# DSS_EDP0_V2A_CORE_VP_REGS_APB register map
Vendor: Texas Instruments
Registers are 32-bit, access not given, reset 0x0 unless marked. A register's access mark holds for its fields unless they carry their own. Offsets are as the file gives them; [hi:lo] are bit positions; {n}, {i} and the like mark numbered series.

## DSS_EDP0_V2A_CORE_VP_REGS_APB (part 3 of 4)
0x226C V2A__CORE_VP__REGS_APB_DP_MTPH_STATUS_p — MTP header status. Relevant only in MST mode.
  [0] MTPH_ACT_STATUS ro — Status of ACT insertion. Returns 1 until ACT sequence completes.
0x2300 V2A__CORE_VP__REGS_APB_DPTX_LANE_EN_p — DPTX lane enable
  [3:0] DPTX_LANE_ENABLE rw — DPTX lane enable each lane as a bit when 1 lane is enabled
0x2304 V2A__CORE_VP__REGS_APB_DPTX_ENHNCD_p — DPTX enhanced mode control register. Relevant only in SST mode. In MST mode it is ignored.
  [0] DPTX_ENHANCED_MODE rw — Enhanced mode control 0x0 - enhanced mode disabled 0x1 - enhanced mode enabled. Enhanced mode should always be enabled if Sink supports it.
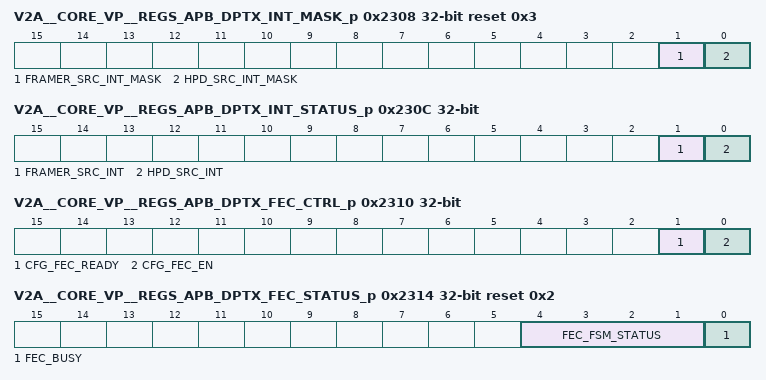
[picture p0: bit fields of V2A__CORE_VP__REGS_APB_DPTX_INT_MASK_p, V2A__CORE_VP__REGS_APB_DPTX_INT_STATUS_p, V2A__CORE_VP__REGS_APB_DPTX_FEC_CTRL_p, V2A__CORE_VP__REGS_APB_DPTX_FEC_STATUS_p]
0x2308 V2A__CORE_VP__REGS_APB_DPTX_INT_MASK_p reset 0x3 — DPTX Interrupt mask.
  [1] FRAMER_SRC_INT_MASK rw — Framer mask interrupt 0x0-interrupt enabled 0x1-interrupt disabled
  [0] HPD_SRC_INT_MASK rw — HPD mask interrupt 0x0-interrupt enabled 0x1-interrupt disabled
0x230C V2A__CORE_VP__REGS_APB_DPTX_INT_STATUS_p — DPTX interrupt status register. This interrupts are tracked by firmware and not accessible directly to the Host processor.
  [1] FRAMER_SRC_INT ro — Framer interrupt - not used.
  [0] HPD_SRC_INT ro — HPD interrupt. Active HIGH. If set further status can be read from HPD_EVENT_DET register. This bit is automatically cleared on read from HPD_EVENT_DET register.
0x2310 V2A__CORE_VP__REGS_APB_DPTX_FEC_CTRL_p — DPTX FEC control register.
  [1] CFG_FEC_READY rw — Equivalent DPCD register FEC_READY, enable alternative CP coding. This bit must be set high before link training if FEC is going to be enabled.
  [0] CFG_FEC_EN rw — FEC Enable 1-enabled 0-disabled. This bit can be changed on when there is no video transmission [and cfg_fec_ready was set before link training].
0x2314 V2A__CORE_VP__REGS_APB_DPTX_FEC_STATUS_p reset 0x2 — FEC status register.
  [4:1] FEC_FSM_STATUS ro — FEC FSM status, 1-FEC is off, 2-generate enable sequence, 4-normal work, 8-generate disable sequence. Used for debug purposes only.
  [0] FEC_BUSY ro — FEC Active status. Set in line with first symbol of FEC_DECODE_EN sequence and de-asserts in line with last symbol of FEC_DECODE_DIS sequence.
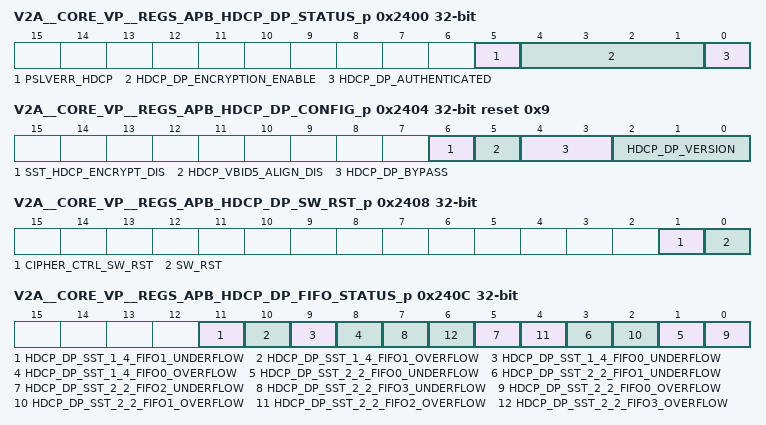
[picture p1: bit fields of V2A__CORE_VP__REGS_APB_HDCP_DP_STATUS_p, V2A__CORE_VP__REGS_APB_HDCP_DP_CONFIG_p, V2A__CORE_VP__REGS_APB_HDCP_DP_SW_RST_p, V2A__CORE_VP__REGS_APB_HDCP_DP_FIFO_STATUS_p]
0x2400 V2A__CORE_VP__REGS_APB_HDCP_DP_STATUS_p — HDCP DP status register.
  [5] PSLVERR_HDCP ro — APB slave error status from HDCP module has been reported when this bit is set to 1.
  [4:1] HDCP_DP_ENCRYPTION_ENABLE ro — Encryption is enabled when this bit is set to 1.
  [0] HDCP_DP_AUTHENTICATED ro — HDCP 1.3 authentication is enabled when this bit is set to 1.
0x2404 V2A__CORE_VP__REGS_APB_HDCP_DP_CONFIG_p reset 0x9 — HDCP DP config register.
  [6] SST_HDCP_ENCRYPT_DIS rw — Disable automatic HDCP encryption in SST mode when cipher is authenticated. This bit can also be set to 1 to disable encryption
  [5] HDCP_VBID5_ALIGN_DIS rw — Debug register, no longer used.
  [4:3] HDCP_DP_BYPASS rw — HDCP DP bypass. No-bypass must be set prior link training if HDCP is going to be used. This field must not be changed during operation. 0x0-No bypass; 0x1-Bypass enabled; All other combinations reserved.
  [2:0] HDCP_DP_VERSION rw — HDCP version. 0x1-HDCP2.2; 0x2-HDCP1.4; Other-Reserved
0x2408 V2A__CORE_VP__REGS_APB_HDCP_DP_SW_RST_p — HDCP DP software reset register
  [1] CIPHER_CTRL_SW_RST rw — Software reset of cipher control logic only.
  [0] SW_RST rw — Software reset.
0x240C V2A__CORE_VP__REGS_APB_HDCP_DP_FIFO_STATUS_p — HDCP DP FIFO status register.
  [11] HDCP_DP_SST_1_4_FIFO1_UNDERFLOW ro — SST HDCP1.4 fifo1 underflow.
  [10] HDCP_DP_SST_1_4_FIFO1_OVERFLOW ro — SST HDCP1.4 fifo1 overflow.
  [9] HDCP_DP_SST_1_4_FIFO0_UNDERFLOW ro — SST HDCP1.4 fifo0 underflow.
  [8] HDCP_DP_SST_1_4_FIFO0_OVERFLOW ro — SST HDCP1.4 fifo0 overflow.
  [2n+1] HDCP_DP_SST_2_2_FIFO{n}_UNDERFLOW ro (n=0..3) — SST HDCP2.2 fifo{n} underflow.
  [2n] HDCP_DP_SST_2_2_FIFO{n}_OVERFLOW ro (n=0..3) — SST HDCP2.2 fifo{n} overflow.
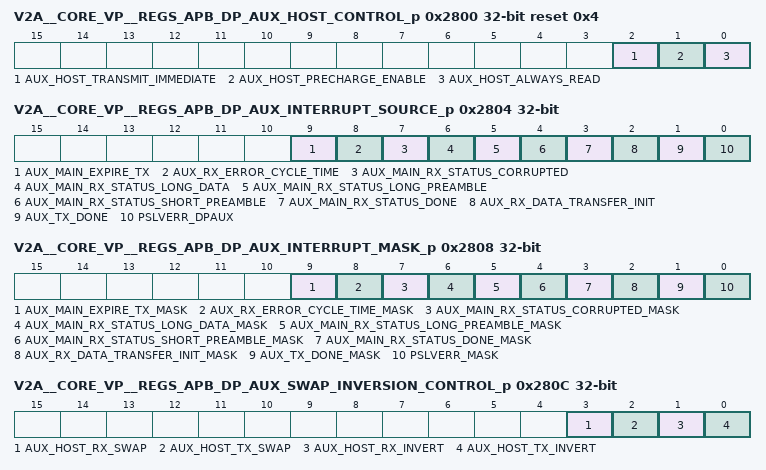
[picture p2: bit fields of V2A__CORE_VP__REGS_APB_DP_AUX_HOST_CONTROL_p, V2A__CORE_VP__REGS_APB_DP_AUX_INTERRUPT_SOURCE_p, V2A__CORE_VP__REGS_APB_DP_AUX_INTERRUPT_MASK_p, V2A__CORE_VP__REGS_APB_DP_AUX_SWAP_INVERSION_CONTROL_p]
0x2800 V2A__CORE_VP__REGS_APB_DP_AUX_HOST_CONTROL_p reset 0x4 — DP AUX control register.
  [2] AUX_HOST_TRANSMIT_IMMEDIATE rw — This bit is used only in DP_OUT mode. If SET, a transaction that comes from the adapter will be sent immediately without waiting for send_external_transaction pulse. If CLEAR, the MC controls the traffic to/from the adapter.
  [1] AUX_HOST_PRECHARGE_ENABLE rw — According to the current standard the tx precharge is done by sending 10 to 16 data_0 on the line before the SYNC. Old standard define the precharge by forcing the AFE to be in precharge mode before transmitting the SYNC.
  [0] AUX_HOST_ALWAYS_READ rw — Normally, the aux_rx is disabled during transmit. Setting this bit allow loopback operation and all transmit transactions will go to the receiver. Used for debug purpose.
0x2804 V2A__CORE_VP__REGS_APB_DP_AUX_INTERRUPT_SOURCE_p — Status of the DP_AUX interrupt sources. These interrupts are tracked by firmware and not accessible directly to the Host processor.
  [9] AUX_MAIN_EXPIRE_TX ro — Timer expire [external] in DP_OUT. Active HIGH. Clear on read.
  [8] AUX_RX_ERROR_CYCLE_TIME ro — Cycle time error. Asserted if aux_rx_last_cycle is less then aux_host_1m_min or greater then aux_host_1m_max. Active HIGH. Clear on read.
  [7] AUX_MAIN_RX_STATUS_CORRUPTED ro — The received transaction corrupted during the data phase [bad STOP, or unaligned STOP]. Active HIGH. Clear on read.
  [6] AUX_MAIN_RX_STATUS_LONG_DATA ro — The received transaction had more than 20 data bytes. Active HIGH. Clear on read.
  [5] AUX_MAIN_RX_STATUS_LONG_PREAMBLE ro — The received transaction had preamble greater than the preamble_max. Active HIGH. Clear on read.
  [4] AUX_MAIN_RX_STATUS_SHORT_PREAMBLE ro — The received transaction had preamble shorter than the preamble_max. Active HIGH. Clear on read.
  [3] AUX_MAIN_RX_STATUS_DONE ro — This module control the packet extraction and packet read from the memory. Active HIGH. Clear on read.
  [2] AUX_RX_DATA_TRANSFER_INIT ro — Rx data transfer may be initiated. Falling edge of the aux_mailbox_empty. Active HIGH. Clear on read.
  [1] AUX_TX_DONE ro — Tx data transfer finished. Active HIGH. Clear on read.
  [0] PSLVERR_DPAUX ro — APB slave error interrupt from DP AUX module. Active HIGH. Clear on read.
0x2808 V2A__CORE_VP__REGS_APB_DP_AUX_INTERRUPT_MASK_p — Mask vector of the DP_AUX interrupt sources.
  [9] AUX_MAIN_EXPIRE_TX_MASK rw — aux_main_expire_external mask 0x0-interrupt enabled 0x1-interrupt disabled
  [8] AUX_RX_ERROR_CYCLE_TIME_MASK rw — aux_rx_error_cycle_time mask 0x0-interrupt enabled 0x1-interrupt disabled
  [7] AUX_MAIN_RX_STATUS_CORRUPTED_MASK rw — aux_main_rx_status_corrupted_mask 0x0-interrupt enabled 0x1-interrupt disabled
  [6] AUX_MAIN_RX_STATUS_LONG_DATA_MASK rw — aux_main_rx_status_long_data_mask 0x0-interrupt enabled 0x1-interrupt disabled
  [5] AUX_MAIN_RX_STATUS_LONG_PREAMBLE_MASK rw — aux_main_rx_status_long_preamble_mask 0x0-interrupt enabled 0x1-interrupt disabled
  [4] AUX_MAIN_RX_STATUS_SHORT_PREAMBLE_MASK rw — aux_main_rx_status_short_preamble_mask 0x0-interrupt enabled 0x1-interrupt disabled
  [3] AUX_MAIN_RX_STATUS_DONE_MASK rw — aux_main_rx_status_done_mask 0x0-interrupt enabled 0x1-interrupt disabled
  [2] AUX_RX_DATA_TRANSFER_INIT_MASK rw — rx_data_transfer_init mask 0x0-interrupt enabled 0x1-interrupt disabled
  [1] AUX_TX_DONE_MASK rw — aux_tx_done_mask 0x0-interrupt enabled 0x1-interrupt disabled
  [0] PSLVERR_MASK rw — Mask for pslverr_dpaux interrupt. 0x0-interrupt enabled 0x1-interrupt disabled
0x280C V2A__CORE_VP__REGS_APB_DP_AUX_SWAP_INVERSION_CONTROL_p — Ordering and inversion of transmit/receive on Auxiliary Channel.
  [3] AUX_HOST_RX_SWAP rw — Shift right [LSB first] of the income data
  [2] AUX_HOST_TX_SWAP rw — Shift right the output data [LSB first]
  [1] AUX_HOST_RX_INVERT rw — Invert rx input and output data to AUXILIARY CHANNEL
  [0] AUX_HOST_TX_INVERT rw — Invert tx input and output data to AUXILIARY CHANNEL
0x2810 V2A__CORE_VP__REGS_APB_DP_AUX_SEND_NACK_TRANSACTION_p — NACK transaction send
  [0] AUX_HOST_SEND_NACK_TRANSACTION rw — Send nack transaction by AUX_TX. This bit is automatically cleared when operation in completed.
0x2814 V2A__CORE_VP__REGS_APB_DP_AUX_CLEAR_RX_p — RX bits clear.
  [0] AUX_HOST_CLEAR_RX rw — Clear all rx bits in register 64,65.This command is an indication that the processing of last receive transaction was completed and the AUX_RX can start looking for new receive transaction. This bit is automatically cleared when operation in completed.
0x2818 V2A__CORE_VP__REGS_APB_DP_AUX_CLEAR_TX_p — TX bits clear.
  [0] AUX_HOST_CLEAR_TX rw — Clear all external bits in registers 64,67.This command used in DP_IN mode. It is an indication that the processing of last external transaction was completed and the DP_AUX can start receive new external transaction from the adapter. This bit is automatically cleared when operation in completed.
0x281C V2A__CORE_VP__REGS_APB_DP_AUX_TIMER_STOP_p — Stop timer operation.
  [0] AUX_HOST_STOP_TIMER rw
0x2820 V2A__CORE_VP__REGS_APB_DP_AUX_TIMER_CLEAR_p — Clear timer operation.
  [0] AUX_HOST_CLEAR_TIMER rw — Stop timer operation. This bit is automatically cleared when operation in completed.
0x2824 V2A__CORE_VP__REGS_APB_DP_AUX_RESET_SW_p — Soft reset of the DP_AUX.
  [0] AUX_HOST_SW_RESET rw — Reset all DP_AUX state machines and clear all the status bits. The registers value remains. [S/W reset]. This bit is automatically cleared when operation in completed.
0x2828 V2A__CORE_VP__REGS_APB_DP_AUX_DIVIDE_2M_p reset 0xB — SYS_CLK and 2 MHz clock ratio. This register is used to ensure correct AUX channel bitrate for different values of a system clock.
  [7:0] AUX_HOST_DIVIDE_2M rw — The ratio between sys_clk and 2MHz, [[sys_clk frequency/2MHz] - 1], for 25MHz sys_clk the value is 11. This register is used by AUX_TX for generating the AUX_TX clock.
0x282C V2A__CORE_VP__REGS_APB_DP_AUX_TX_PREACHARGE_LENGTH_p reset 0x10 — Pre charge field length.
  [5:0] AUX_HOST_PRECHARGE_LENGTH rw — Length of pre charge field, standard definition is 10 to 16 bits/clocks.
0x2830 V2A__CORE_VP__REGS_APB_DP_AUX_FREQUENCY_1M_MAX_p reset 0x22 — Maximum legal receiving frequency.
  [10:0] AUX_HOST_1M_MAX rw — The maximum legal frequency receiving from the line by the standard is 1.25MHz.The calculation is:[1.25 MHz cycle time]/[sys_clk[-15%] cycle time] 800/46 =17
0x2834 V2A__CORE_VP__REGS_APB_DP_AUX_FREQUENCY_1M_MIN_p reset 0x9 — Minimum legal receiving frequency.
  [10:0] AUX_HOST_1M_MIN rw — The minimum legal frequency receiving from the line by the standard is 0.83MHz.The calculation is:[0.83 MHz cycle time]/[sys_clk[+15%] cycle time] 1200/34 =35
0x2838 V2A__CORE_VP__REGS_APB_DP_AUX_RX_PRE_MIN_p reset 0x1A — Minimum received preamble length
  [5:0] AUX_HOST_PRE_MIN rw — Valid minimum length of preamble during receive. The standard defines pre_min=26 The value of this register should be greater then the average_number_of_cycles defined in reg 0 [2 , 4 or 8 ]
0x283C V2A__CORE_VP__REGS_APB_DP_AUX_RX_PRE_MAX_p reset 0x20 — Maximum received preamble length.
  [5:0] AUX_HOST_PRE_MAX rw — Valid maximum length of preamble during receive. The standard defines pre_max = 32
0x2840 V2A__CORE_VP__REGS_APB_DP_AUX_TIMER_PRESET_p reset 0x1D4C — DP_AUX_MAIN start value
  [15:0] AUX_HOST_TIMER_PRESET rw — The preset value of the timer in DP_IN mode. With sys_clk= 25MHz the Timer can measure up to ~2500 micro seconds. The defaults value is 300us [0x1D4c]
0x2844 V2A__CORE_VP__REGS_APB_DP_AUX_NACK_FORMAT_p reset 0x20 — Transmit pattern.
  [7:0] AUX_HOST_NACK_FORMAT rw — Nack or defer pattern for transmit [ 00100000 for defer, 00010000 for nack]
0x2848 V2A__CORE_VP__REGS_APB_DP_AUX_TX_DATA_p — AUX Mailbox write data.
  [9:0] MAILBOX_TX_DATA rw — TX data byte written to the mailbox. It is written 20 times and directly transferred into TX mailbox. First 8 bits are regular data. When the first data is transferred into mailbox mailbox_tx_data[8] [frame start] is set to 1. When the last data is transferred into mailbox, mailbox_tx_data[9] [frame_end] is set to 1.
0x284C V2A__CORE_VP__REGS_APB_DP_AUX_RX_DATA_p — AUX Mailbox read data.
  [9:0] MAILBOX_RX_DATA ro — Read data from the mailbox. Whenever read to this register occurs, aux_mailbox_read to RX Mailbox shall be asserted for one clock cycle.
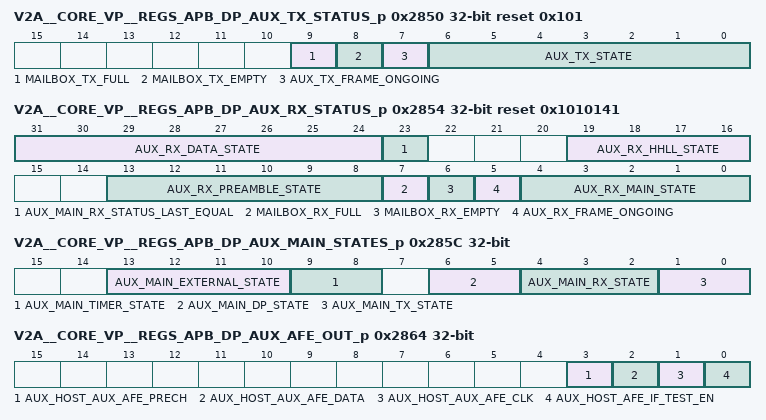
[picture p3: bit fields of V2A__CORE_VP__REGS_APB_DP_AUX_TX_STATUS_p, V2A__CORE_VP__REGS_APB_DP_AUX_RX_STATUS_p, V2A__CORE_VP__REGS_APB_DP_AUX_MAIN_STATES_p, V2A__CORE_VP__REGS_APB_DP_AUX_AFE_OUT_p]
0x2850 V2A__CORE_VP__REGS_APB_DP_AUX_TX_STATUS_p reset 0x101 — AUX_TX status.
  [9] MAILBOX_TX_FULL ro — AUX Mailbox TX full flag.
  [8] MAILBOX_TX_EMPTY ro — AUX Mailbox TX empty flag.
  [7] AUX_TX_FRAME_ONGOING ro — Frame transmission status.
  [6:0] AUX_TX_STATE ro — Aux_tx state machine register.
0x2854 V2A__CORE_VP__REGS_APB_DP_AUX_RX_STATUS_p reset 0x1010141 — AUX_RX status
  [31:24] AUX_RX_DATA_STATE ro — AUX_RX SM state.
  [23] AUX_MAIN_RX_STATUS_LAST_EQUAL ro — The receive transaction is equal to the previous transaction.
  [19:16] AUX_RX_HHLL_STATE ro — AUX_RX hhll state machine register.
  [13:8] AUX_RX_PREAMBLE_STATE ro — AUX_RX preamble state machine register. Used only for debug.
  [7] MAILBOX_RX_FULL ro — AUX Mailbox RX full flag.
  [6] MAILBOX_RX_EMPTY ro — AUX Mailbox RX empty flag.
  [5] AUX_RX_FRAME_ONGOING ro — Frame reception status.
  [4:0] AUX_RX_MAIN_STATE ro — AUX_RX main state machine register. Used only for debug purpose.
0x2858 V2A__CORE_VP__REGS_APB_DP_AUX_RX_CYCLE_COUNTER_p — AUX RX counter status.
  [10:0] AUX_RX_CYCLE_COUNTER ro — Count system clocks from last change in the auxiliary line input.
0x285C V2A__CORE_VP__REGS_APB_DP_AUX_MAIN_STATES_p — DP_AUX MAIN State Machines status. Used only for debug purpose.
  [13:10] AUX_MAIN_EXTERNAL_STATE ro — AUX_MAIN external state machine register.
  [9:8] AUX_MAIN_TIMER_STATE ro — AUX_MAIN timer state machine.
  [6:5] AUX_MAIN_DP_STATE ro — AUX_MAIN dp state machine.
  [4:2] AUX_MAIN_RX_STATE ro — AUX_MAIN rx state machine.
  [1:0] AUX_MAIN_TX_STATE ro — AUX_MAIN tx state machine.
0x2860 V2A__CORE_VP__REGS_APB_DP_AUX_MAIN_TIMER_p — DP_AUX MAIN timer status.
  [15:0] AUX_MAIN_TIMER ro
0x2864 V2A__CORE_VP__REGS_APB_DP_AUX_AFE_OUT_p — Test mode configuration.
  [3] AUX_HOST_AUX_AFE_PRECH rw — Drive the aux_data_prech output to the AFE when aux_host_afe_if_test_en [bit 0 ] is set.
  [2] AUX_HOST_AUX_AFE_DATA rw — Drive the aux_data_out output to the AFE when aux_host_afe_if_test_en [bit 0 ] is set.
  [1] AUX_HOST_AUX_AFE_CLK rw — Drive the aux_clk_out output to the AFE when aux_host_afe_if_test_en [bit 0 ] is set.
  [0] AUX_HOST_AFE_IF_TEST_EN rw — TESTER mode enable. Give the TESTER direct interface to the AFE_AUX.
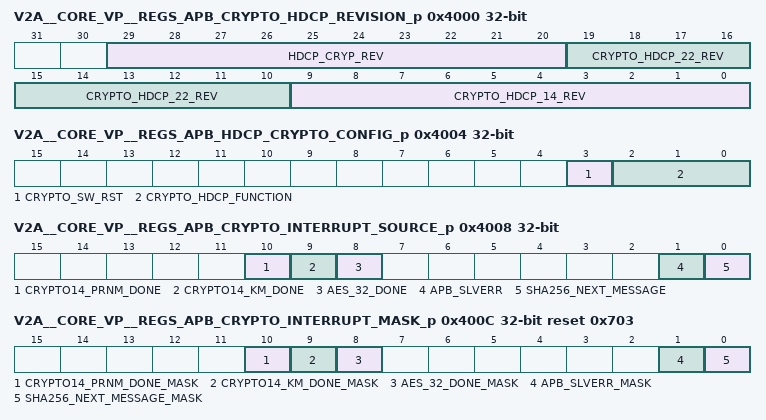
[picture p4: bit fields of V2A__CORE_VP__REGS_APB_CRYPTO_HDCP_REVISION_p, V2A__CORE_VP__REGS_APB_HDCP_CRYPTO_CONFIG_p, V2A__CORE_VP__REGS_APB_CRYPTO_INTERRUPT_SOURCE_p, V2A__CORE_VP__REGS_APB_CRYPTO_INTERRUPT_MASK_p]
0x4000 V2A__CORE_VP__REGS_APB_CRYPTO_HDCP_REVISION_p — Contains the revision of the internal HDCP 1.4 and 2.2 module.
  [29:20] HDCP_CRYP_REV ro — Revision of the HDCP Crypto block.
  [19:10] CRYPTO_HDCP_22_REV ro — Revision of the HDCP Crypto 2.2 block.
  [9:0] CRYPTO_HDCP_14_REV ro — Revision of the HDCP Crypto 1.4 block.
0x4004 V2A__CORE_VP__REGS_APB_HDCP_CRYPTO_CONFIG_p — Contains global configuration information for the HDCP Crypto module.
  [3] CRYPTO_SW_RST rw — Software reset for the Crypto module.
  [2:0] CRYPTO_HDCP_FUNCTION rw — Enables a version of the Crypto function: 0x0 - HDCP 1.4 0x1 - HDCP 2.2 Other - Reserved
0x4008 V2A__CORE_VP__REGS_APB_CRYPTO_INTERRUPT_SOURCE_p — Contains the status of the HDCP interrupt sources. These interrupts are used by firmware and not directly visible to the Host processor.
  [10] CRYPTO14_PRNM_DONE ro — LFSR and block output finished calculation. Active HIGH. Clear on read.
  [9] CRYPTO14_KM_DONE ro — Done reading/calculating Km. Active HIGH. Clear on read.
  [8] AES_32_DONE ro — Asserted when the rising edge of the AES-32 done output is detected. Active HIGH. Clear on read.
  [1] APB_SLVERR ro — APB slave error. Asserted when APB address is out of address range. Active HIGH. Clear on read.
  [0] SHA256_NEXT_MESSAGE ro — Asserted when the rising edge of the SHA256 done output is detected. Active HIGH. Clear on read.
0x400C V2A__CORE_VP__REGS_APB_CRYPTO_INTERRUPT_MASK_p reset 0x703 — Contains the mask vector of the HDCP interrupt sources.
  [10] CRYPTO14_PRNM_DONE_MASK rw — Set to 1 to mask the crypto14_prnm_done interrupt. 0x0-interrupt enabled 0x1-interrupt disabled
  [9] CRYPTO14_KM_DONE_MASK rw — Set to 1 to mask the crypto14_km_done interrupt. 0x0-interrupt enabled 0x1-interrupt disabled
  [8] AES_32_DONE_MASK rw — Set to 1 to mask the AES32_done interrupt. 0x0-interrupt enabled 0x1-interrupt disabled
  [1] APB_SLVERR_MASK rw — Set to 1 for the apb_slverr interrupt. 0x0-interrupt enabled 0x1-interrupt disabled
  [0] SHA256_NEXT_MESSAGE_MASK rw — Set to 1 to mask the SHA256_done interrupt. 0x0-interrupt enabled 0x1-interrupt disabled
0x4018 V2A__CORE_VP__REGS_APB_CRYPTO22_CONFIG_p — Contains global configuration information for the HDCP 2.2 Crypto module
  [0] SHA_256_START rw — Set to 1 for Sha-256 start.
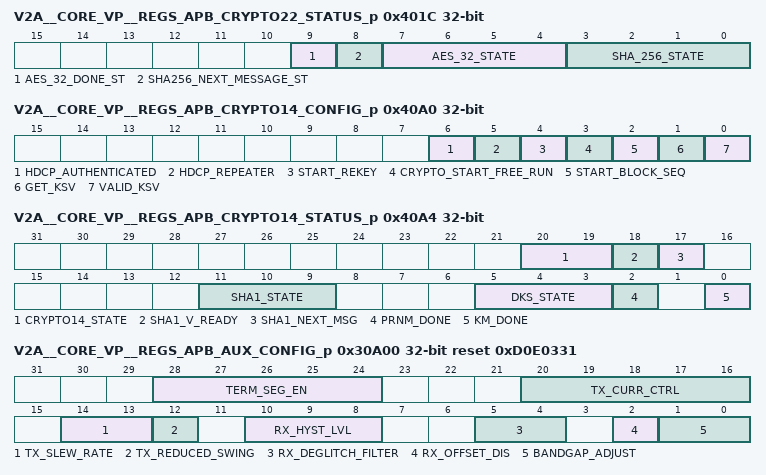
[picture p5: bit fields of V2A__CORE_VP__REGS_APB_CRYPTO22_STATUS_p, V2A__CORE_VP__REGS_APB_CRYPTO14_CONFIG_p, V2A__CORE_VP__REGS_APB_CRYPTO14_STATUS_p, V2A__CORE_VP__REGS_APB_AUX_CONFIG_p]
0x401C V2A__CORE_VP__REGS_APB_CRYPTO22_STATUS_p — Crypto 2.2 global status register.
  [9] AES_32_DONE_ST ro — Asserted when the rising edge of the AES-32 done output is detected.
  [8] SHA256_NEXT_MESSAGE_ST ro — Asserted when the SHA-256 module is ready to receive the next message.
  [7:4] AES_32_STATE ro — AES-32 current state.
  [3:0] SHA_256_STATE ro — SHA-256 current state.
0x403C V2A__CORE_VP__REGS_APB_SHA_256_DATA_IN_p rw — Holds 32-bit input data word of the SHA-256 module.
  [31:0] SHA_256_DATA_IN — Holds the 32-bit input data word of the SHA-256 module.
0x4050 V2A__CORE_VP__REGS_APB_SHA_256_DATA_OUT_0_p ro — Result of operation SHA-256 - 1' dw
  [31:0] SHA_256_DATA_OUT_0 — Holds the least significant 32-bits word of the 256-bits output data word of the SHA-256 module.
0x4054 V2A__CORE_VP__REGS_APB_SHA_256_DATA_OUT_1_p ro — Result of operation SHA-256 - 2' dw
  [31:0] SHA_256_DATA_OUT_1 — Holds the next significant 32-bits word of the 256-bits output data word of the SHA-256 module.
0x4058 V2A__CORE_VP__REGS_APB_SHA_256_DATA_OUT_2_p ro — Result of operation SHA-256 - 3' dw
  [31:0] SHA_256_DATA_OUT_2 — Holds the next significant 32-bits word of the 256-bits output data word of the SHA-256 module
{0x4050+4i} V2A__CORE_VP__REGS_APB_SHA_256_DATA_OUT_{i}_p ro (i=3..6) — Result of operation SHA-256 - {i+1}' dw
  [31:0] SHA_256_DATA_OUT_{i} — Holds the next significant 32-bits word of the 256-bits output data word of the SHA-256 module.
0x406C V2A__CORE_VP__REGS_APB_SHA_256_DATA_OUT_7_p ro — Result of operation SHA-256 - 8' dw
  [31:0] SHA_256_DATA_OUT_7 — Holds the most significant 32-bits word of the 256-bits output data word of the SHA-256 module.
0x4070 V2A__CORE_VP__REGS_APB_AES_32_KEY_0_p rw — Input key word of the AES-32 module - 1' dw
  [31:0] AES_32_KEY_0 — Holds the least significant 32-bits word of the 128-bits input key word of the AES-32 module.
0x4074 V2A__CORE_VP__REGS_APB_AES_32_KEY_1_p rw — Input key word of the AES-32 module - 2' dw
  [31:0] AES_32_KEY_1 — Holds the next significant 32-bits word of the 128-bits input key word of the AES-32 module.
0x4078 V2A__CORE_VP__REGS_APB_AES_32_KEY_2_p rw — Input key word of the AES-32 module - 3' dw
  [31:0] AES_32_KEY_2 — Holds the next significant 32-bits word of the 128-bits input key word of the AES-32 module.
0x407C V2A__CORE_VP__REGS_APB_AES_32_KEY_3_p rw — Input key word of the AES-32 module - 4' dw
  [31:0] AES_32_KEY_3 — Holds the most significant 32-bits word of the 128-bits input key word of the AES-32 module.
0x4080 V2A__CORE_VP__REGS_APB_AES_32_DATA_IN_p rw — Input data word to the AES-32 module
  [31:0] AES_32_DATA_IN — Holds the input data word to the AES-32 module.
0x4084 V2A__CORE_VP__REGS_APB_AES_32_DATA_OUT_0_p ro — AES-32 module - 128-bits output data word - 1' dw
  [31:0] AES_32_DATA_OUT_0 — Holds the least significant 32-bits word of the 128-bits output data word of the AES-32 module.
0x4088 V2A__CORE_VP__REGS_APB_AES_32_DATA_OUT_1_p ro — AES-32 module - 128-bits output data word - 2' dw
  [31:0] AES_32_DATA_OUT_1 — Holds the next significant 32-bits word of the 128-bits output data word of the AES-32 module.
0x408C V2A__CORE_VP__REGS_APB_AES_32_DATA_OUT_2_p ro — AES-32 module - 128-bits output data word - 3' dw
  [31:0] AES_32_DATA_OUT_2 — Holds the next significant 32-bits word of the 128-bits output data word of the AES-32 module.
0x4090 V2A__CORE_VP__REGS_APB_AES_32_DATA_OUT_3_p ro — AES-32 module - 128-bits output data word - 4' dw
  [31:0] AES_32_DATA_OUT_3 — Holds the most significant 32-bits word of the 128-bits output data word of the AES-32 module.
0x40A0 V2A__CORE_VP__REGS_APB_CRYPTO14_CONFIG_p — Contains global configuration information for the HDCP 1.4 Crypto module
  [6] HDCP_AUTHENTICATED rw — Authenticated finished.
  [5] HDCP_REPEATER rw — Repeater bit : 0: for the receiver, 1: for the repeater
  [4] START_REKEY rw — Crypto 1.4 command to start hdcpRekeyCipher
  [3] CRYPTO_START_FREE_RUN rw — Crypto 1.4 command to start free running enable for operation hdcpRngCipher
  [2] START_BLOCK_SEQ rw — Crypto 1.4 command to start LFSR calculation
  [1] GET_KSV rw — Read it's own KSV enable bit.'0' reading not allowed'1' start reading.
  [0] VALID_KSV rw — Enable for Km calculation. When high, start calculating Km. Indicates a good moment for ri_out sampling.
0x40A4 V2A__CORE_VP__REGS_APB_CRYPTO14_STATUS_p — Contains global status information for the HDCP 1.4 Crypto module
  [20:19] CRYPTO14_STATE ro — Crypto operation SM state: Possible values: 00- HDCP_RNG_CIPHER 01 - HDCP_BLOCK_CIPHER 10 - HDCP_STREAM_CIPHER 11 - HDCP_REKEY_CIPHER
  [18] SHA1_V_READY ro — Indication that V value from SHA-1 CRYPTO14_SHA1_V_VALUE_4 is ready.
  [17] SHA1_NEXT_MSG ro — Request for the next message block. When set high, CRYPTO14_SHA1_MSG_DATA_0-15 registers shall be written.
  [11:9] SHA1_STATE ro — Current state for Crypto 1.4 SHA-1 FSM. Used for debug purpose. Possible values: 000 - IDLE 001 - PREPARE 010 - CALCULATE 011 - RESULT 100 - BLOCK_WAIT
  [5:3] DKS_STATE ro — Crypto 1.4 DKS current state. Used for debug purpose. Possible values: 000 - HDCP_IDLE_KSV 010 - HDCP_IDLE 100 - HDCP_PRECALC 101 - HDCP_POSTCALC 110 - HDCP_CALC 111 - HDCP_READY
  [2] PRNM_DONE ro — LFSR and block output finished calculation.
  [0] KM_DONE ro — Done reading/calculating Km. Used as interrupt event.
0x40A8 V2A__CORE_VP__REGS_APB_CRYPTO14_PRNM_OUT_p — Contains 24-bit pseudo random data
  [23:0] PRNM_OUT ro — 24-bit pseudo-random data.
0x40AC V2A__CORE_VP__REGS_APB_CRYPTO14_KM_0_p ro — Contains the first word of the Km value
  [31:0] CRYPTO14_KM_0 — Holds the first word of the Km value.
0x40B0 V2A__CORE_VP__REGS_APB_CRYPTO14_KM_1_p — Contains the most significant 3 bytes of the Km value
  [23:0] CRYPTO14_KM_1 ro — Holds the most significant 3 bytes of the Km value.
0x40B4 V2A__CORE_VP__REGS_APB_CRYPTO14_AN_0_p rw — First word of An value generated by hdcpRngCipher operation.
  [31:0] CRYPTO14_AN_0 — Holds the first 4 bytes of the An value.
0x40B8 V2A__CORE_VP__REGS_APB_CRYPTO14_AN_1_p rw — Second word of An value generated by hdcpRngCipher operation
  [31:0] CRYPTO14_AN_1 — Holds the most significant 4 bytes of the An value.
0x40BC V2A__CORE_VP__REGS_APB_CRYPTO14_YOUR_KSV_0_p rw — First 32 bits of the KSV from the other HDCP device
  [31:0] CRYPTO14_YOUR_KSV_0 — Holds the first 32 bits of the KSV from the other HDCP device.
0x40C0 V2A__CORE_VP__REGS_APB_CRYPTO14_YOUR_KSV_1_p — Last byte of the KSV from other HDCP device
  [7:0] CRYPTO14_YOUR_KSV_1 rw — Holds the last byte of the KSV from other HDCP device
0x40C4 V2A__CORE_VP__REGS_APB_CRYPTO14_MI_0_p ro — Mi value - 1' dw
  [31:0] CRYPTO14_MI_0 — Mi value first 32 bits
0x40C8 V2A__CORE_VP__REGS_APB_CRYPTO14_MI_1_p ro — Mi value - 2' dw
  [31:0] CRYPTO14_MI_1 — Mi value second 32 bits
0x40CC V2A__CORE_VP__REGS_APB_CRYPTO14_TI_0_p — Ti value
  [15:0] CRYPTO14_TI_0 ro
0x40D0 V2A__CORE_VP__REGS_APB_CRYPTO14_KI_0_p ro — First 32 bits of the Ki frame key from this HDCP device
  [31:0] CRYPTO14_KI_0 — Holds the first 32 bits of the Ki frame key from this HDCP device.
0x40D4 V2A__CORE_VP__REGS_APB_CRYPTO14_KI_1_p — Last 3 bytes of the Ki frame key from this HDCP device.
  [23:0] CRYPTO14_KI_1 ro — Holds the last 3 bytes of the Ki frame key from this HDCP device.
0x40D8 V2A__CORE_VP__REGS_APB_CRYPTO14_BLOCKS_NUM_p rw — This register defines number of iterations for SHA-1 calculations
  [31:0] BLOCKS_NUM — Number of iterations for SHA-1 calculation.
0x40DC V2A__CORE_VP__REGS_APB_CRYPTO14_KEY_MEM_DATA_0_p rw — Key memory control register. Writing data to this register transfers data to the key RAM. This is input for DKS block. First 32 bits
  [31:0] KEY_MEM_DATA_0 — Output data from keys RAM. Input for DKS block. First 32 bits.
0x40E0 V2A__CORE_VP__REGS_APB_CRYPTO14_KEY_MEM_DATA_1_p — Key memory control register. Writing data to this register transfers data to the key RAM. When data is written to this register, pulse key_mem_vld shall be also generated to the core_clk clock domain, as indication of new key_mem_data. This is input for DKS block. Last 3 bytes
  [23:0] KEY_MEM_DATA_1 rw — Output data from keys RAM. Input for DKS block. Last 3 bytes.
0x40E4 V2A__CORE_VP__REGS_APB_CRYPTO14_SHA1_MSG_DATA_p rw — SHA1 message control register. 32-bit word for SHA-1 message. Input for SHA-1 block. Writing data to this register transfers data to the SHA-1 block. Write to this register shall be repeated 16 times.
  [31:0] SHA1_MSG_DATA — 32-bit word for SHA-1 message. Input for SHA-1 block.
0x40E8 V2A__CORE_VP__REGS_APB_CRYPTO14_SHA1_V_VALUE_0_p ro reset 0x67452301 — SHA1 message status register. First 32-bit word for SHA-1 calculation. Output from SHA-1 block
  [31:0] V_VALUE_0 — First 32-bit word for SHA-1 calculation value. Output from SHA-1 block.
0x40EC V2A__CORE_VP__REGS_APB_CRYPTO14_SHA1_V_VALUE_1_p ro reset 0xEFCDAB89 — SHA1 message status register. Second 32-bit word for SHA-1 calculation. Output from SHA-1 block
  [31:0] V_VALUE_1 — Second 32-bit word for SHA-1 calculation value. Output from SHA-1 block.
0x40F0 V2A__CORE_VP__REGS_APB_CRYPTO14_SHA1_V_VALUE_2_p ro reset 0x98BADCFE — SHA1 message status register. Third 32-bit word for SHA-1 calculation. Output from SHA-1 block
  [31:0] V_VALUE_2 — Third 32-bit word for SHA-1 calculation value. Output from SHA-1 block.
0x40F4 V2A__CORE_VP__REGS_APB_CRYPTO14_SHA1_V_VALUE_3_p ro reset 0x10325476 — SHA1 message status register. Third 32-bit word for SHA-1 calculation. Output from SHA-1 block
  [31:0] V_VALUE_3 — 4th 32-bit word for SHA-1 calculation value. Output from SHA-1 block.
0x40F8 V2A__CORE_VP__REGS_APB_CRYPTO14_SHA1_V_VALUE_4_p ro reset 0xC3D2E1F0 — SHA1 message status register. 5th 32-bit word for SHA-1 calculation. Output from SHA-1 block
  [31:0] V_VALUE_4 — 5th 32-bit word for SHA-1 calculation value. Output from SHA-1 block.
0x10000 V2A__CORE_VP__REGS_APB_IRAM_REG_p rw — Xtensa Instruction RAM address space. Accessed only during boot mode to load firmware.
  [31:0] IRAM_DATA
0x20000 V2A__CORE_VP__REGS_APB_DRAM_REG_p rw — Xtensa Data RAM address space. Accessed only during boot mode to load firmware.
  [31:0] DRAM_DATA
0x30A00 V2A__CORE_VP__REGS_APB_AUX_CONFIG_p reset 0xD0E0331 — AUX Configuration Register
  [28:24] TERM_SEG_EN rw — Enables output resistor segments for termination impedance.
  [20:16] TX_CURR_CTRL rw — TX current for output diff pair.
  [14:13] TX_SLEW_RATE rw — TX slew rate adjust.
  [12] TX_REDUCED_SWING rw — Control for lowering AUX transmitter swing level.
  [10:8] RX_HYST_LVL rw — Hysteresis control for AUX receiver front end.
  [5:4] RX_DEGLITCH_FILTER rw — Suppresses high-frequency pulses on AUX receiver output.
  [2] RX_OFFSET_DIS rw — Disables internal receiver cmn mode offset.
  [1:0] BANDGAP_ADJUST rw — Bandgap startup circuit adjust.
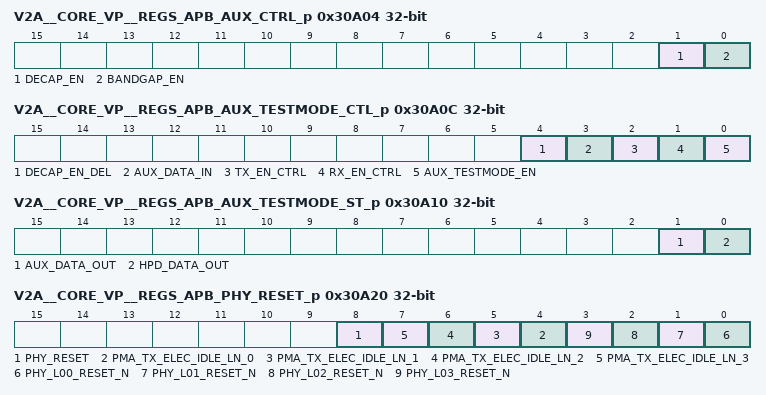
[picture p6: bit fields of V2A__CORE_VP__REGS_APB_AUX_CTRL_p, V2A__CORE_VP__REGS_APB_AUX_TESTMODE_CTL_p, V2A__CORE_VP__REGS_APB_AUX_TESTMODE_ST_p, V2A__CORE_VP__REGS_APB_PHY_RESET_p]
0x30A04 V2A__CORE_VP__REGS_APB_AUX_CTRL_p — AUX Control Register
  [1] DECAP_EN rw — Decap enable. Active HIGH. Asserted as long as DPTX system is enabled.
  [0] BANDGAP_EN rw — Bandgap enable. Active HIGH. Asserted when AUX channel needs to be used for request/response traffic - can be disabled after response is received if channel will not be needed for more than 4.5 microseconds.
0x30A08 V2A__CORE_VP__REGS_APB_AUX_ATBSEL_p — AUX_ATBSEL
  [7:0] AUXIP_ATBSEL_ONEHOT rw
0x30A0C V2A__CORE_VP__REGS_APB_AUX_TESTMODE_CTL_p — AUX IP test control register.
  [4] DECAP_EN_DEL rw — decap_en_del test value. Reflected at the decap_en_del output when aux_testmode_en=1
  [3] AUX_DATA_IN rw — aux_data_in test value. Reflected at the aux_data_in output when aux_testmode_en=1
  [2] TX_EN_CTRL rw — tx_en test value. Reflected at the tx_en output when aux_testmode_en=1
  [1] RX_EN_CTRL rw — rx_en test value. Reflected at the rx_en output when aux_testmode_en=1
  [0] AUX_TESTMODE_EN rw — AUX test enable. 0 - Test mode disabled 1 - test mode enabled, rx_en, tx_en, aux_data_in and decap_en_del are driven directly from the control rgisters
0x30A10 V2A__CORE_VP__REGS_APB_AUX_TESTMODE_ST_p — AUX IP interface status.
  [1] AUX_DATA_OUT ro — Raw status of aux_data_out output from AUX IP
  [0] HPD_DATA_OUT ro — Raw status of HPD output from AUX IP
0x30A20 V2A__CORE_VP__REGS_APB_PHY_RESET_p — PHY Reset Control Register
  [8] PHY_RESET rw — 0 - reset all PHY logic for the entire PHY with the exception of the PHY APB registers, 1 - turn off reset. PHY reset is active LOW.
  [n+4] PMA_TX_ELEC_IDLE_LN_{n} rw (n=0..3) — PMA Tx electrical idle for line {n}. 1 - Tx differential output placed into electrical idle, 0 - transmit data.
  [n] PHY_L{n:02}_RESET_N rw (n=0..3) — 0 - turn on PHY l{n:02} reset with the exception of the PHY APB registers, 1 - turn off reset. PHY l{n:02} reset is active LOW.
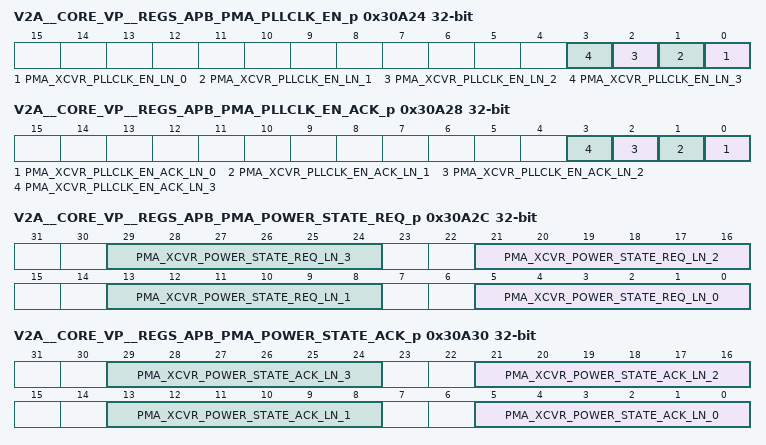
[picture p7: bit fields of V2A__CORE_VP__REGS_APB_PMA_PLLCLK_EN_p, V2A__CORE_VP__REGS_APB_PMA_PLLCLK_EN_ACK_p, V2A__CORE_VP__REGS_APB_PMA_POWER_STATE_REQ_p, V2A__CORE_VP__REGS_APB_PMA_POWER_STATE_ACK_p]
0x30A24 V2A__CORE_VP__REGS_APB_PMA_PLLCLK_EN_p — PHY Link PLL Clock Enable Register
  [n] PMA_XCVR_PLLCLK_EN_LN_{n} rw (n=0..3) — Link PLL clock enable used to cleanly turn off the data rate clock in the PMA for line {n}, 1 - enable Line {n} PLL clock. 0 - disable PLL clock.
0x30A28 V2A__CORE_VP__REGS_APB_PMA_PLLCLK_EN_ACK_p — PHY Link PLL Clock Status Register
  [n] PMA_XCVR_PLLCLK_EN_ACK_LN_{n} ro (n=0..3) — Link PLL clock enable acknowledgement, indicates whether the data rate clock in the PMA for line {n} is running. Active HIGH.
0x30A2C V2A__CORE_VP__REGS_APB_PMA_POWER_STATE_REQ_p — PHY Link Power State Request Register. Please refer to PHY Specification for detailed power state values
  [8n+5:8n] PMA_XCVR_POWER_STATE_REQ_LN_{n} rw (n=0..3) — Change the link power state. When the link has completed the transition to the requested power state, the state will be reflected on pma_xcvr_power_state_ack_ln_{n}.
0x30A30 V2A__CORE_VP__REGS_APB_PMA_POWER_STATE_ACK_p — PHY Link Power State Status Register
  [8n+5:8n] PMA_XCVR_POWER_STATE_ACK_LN_{n} ro (n=0..3) — Link power state acknowledgement, this signal provides indication that a power state change request has completed.
0x30A34 V2A__CORE_VP__REGS_APB_PMA_CMN_READY_p — PMA Operation Status Register
  [0] PMA_CMN_READY ro — PMA common ready, 1 = PMA common is ready for operation. Used as part of Raw SerDes startup sequence and power state changes.
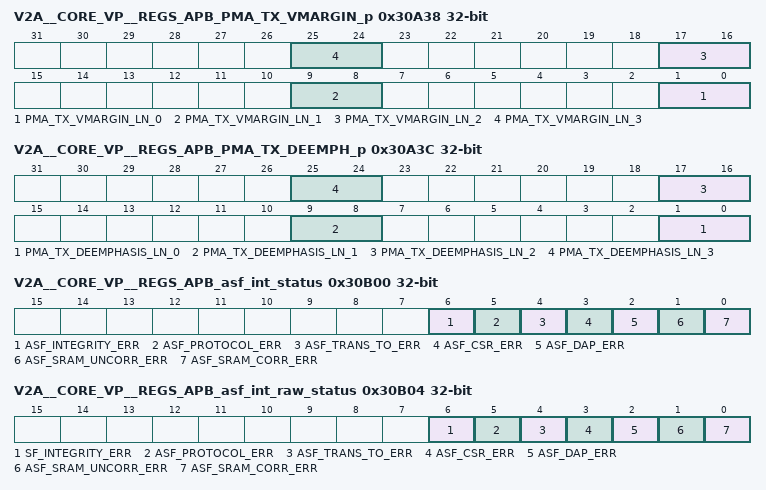
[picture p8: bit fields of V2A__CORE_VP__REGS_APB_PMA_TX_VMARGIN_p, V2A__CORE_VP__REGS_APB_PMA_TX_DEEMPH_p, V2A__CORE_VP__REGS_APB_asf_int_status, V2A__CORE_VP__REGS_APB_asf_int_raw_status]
0x30A38 V2A__CORE_VP__REGS_APB_PMA_TX_VMARGIN_p — PMA Tx Voltage Margin Control Register. Please refer to PHY Specification for Voltage Margin settings.
  [8n+1:8n] PMA_TX_VMARGIN_LN_{n} rw (n=0..3) — Drives PMA input tx_vmargin_ln_{n} for the associated lane. Drive with desired initial transit margin upon de-assertion of phy_reset_n.
0x30A3C V2A__CORE_VP__REGS_APB_PMA_TX_DEEMPH_p — PMA Tx Deemphasis Level Control Register. Please refer to PHY Specification for Deemphasis Level settings.
  [8n+1:8n] PMA_TX_DEEMPHASIS_LN_{n} rw (n=0..3) — Drives PMA input tx_deemphasis_ln_{n} for the associated lane. Drives with desired initial deemphasis setting upon de-assertion of phy_reset_n.
0x30A60 V2A__CORE_VP__REGS_APB_asf_ips_ctrl reset 0x1 — ASF control register, imlemented only when ASF support is enabled in IP configuration
  [0] IF_ADDR_PARCHECK_EN rw — When set, enables parity check at APB/SAPB address bus. This bit should be enabled during normal operation but disabled in test mode when internal parity checkers are verified
0x30B00 V2A__CORE_VP__REGS_APB_asf_int_status — ASF Interrupt Status Register. This register indicates the source of ASF interrupts. The corresponding bit in the mask register must be clear for a bit to be set. If any bit is set in this register the asf_fatal or asf_nonfatal signal will be asserted. Writing to either raw or masked status registers, clear both registers. For test purposes, trigger signal interrupt event by writing to the ASF interrupt status test register.
  [6] ASF_INTEGRITY_ERR rw — Integrity error interrupt,1 is active, 0 is not active
  [5] ASF_PROTOCOL_ERR rw — Protocol error interrupt,1 is active, 0 is not active
  [4] ASF_TRANS_TO_ERR rw — Transaction timeouts error interrupt,1 is active, 0 is not active
  [3] ASF_CSR_ERR rw — Configuration and status registers error interrupt,1 is active, 0 is not active
  [2] ASF_DAP_ERR rw — Data and address paths parity error interrupt,1 is active, 0 is not active
  [1] ASF_SRAM_UNCORR_ERR rw — SRAM uncorrectable error interrupt,1 is active, 0 is not active
  [0] ASF_SRAM_CORR_ERR rw — SRAM correctable error interrupt,1 is active, 0 is not active
0x30B04 V2A__CORE_VP__REGS_APB_asf_int_raw_status — ASF Interrupt Raw Status Register. A bit set in this raw register indicates a source of ASF fault in the corresponding feature. Writing to either raw or masked status registers, clear both registers. For test purposes, trigger signal interrupt event by writing to the ASF interrupt status test register.
  [6] SF_INTEGRITY_ERR rw — Integrity error interrupt,1 is active, 0 is not active
  [5] ASF_PROTOCOL_ERR rw — Protocol error interrupt,1 is active, 0 is not active
  [4] ASF_TRANS_TO_ERR rw — Transaction timeouts error interrupt,1 is active, 0 is not active
  [3] ASF_CSR_ERR rw — Configuration and status registers error interrupt,1 is active, 0 is not active
  [2] ASF_DAP_ERR rw — Data and address paths parity error interrupt,1 is active, 0 is not active
  [1] ASF_SRAM_UNCORR_ERR rw — SRAM uncorrectable error interrupt,1 is active, 0 is not active
  [0] ASF_SRAM_CORR_ERR rw — SRAM correctable error interrupt,1 is active, 0 is not active
